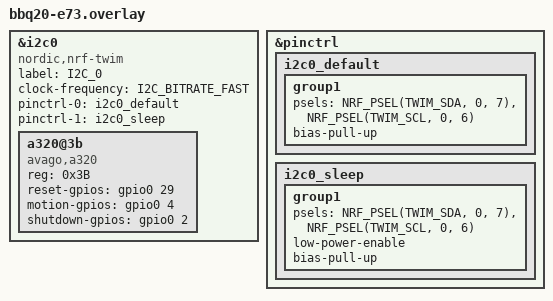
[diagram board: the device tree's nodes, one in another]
&i2c0 {
    a320@3b {
        compatible = "avago,a320";
        status = "okay";
        reg = <0x3B>;
        reset-gpios = <&gpio0 29 GPIO_ACTIVE_HIGH>;  // 复位引脚
        motion-gpios = <&gpio0 4 GPIO_ACTIVE_HIGH>; // 运动中断引脚
        shutdown-gpios= <&gpio0 2 GPIO_ACTIVE_HIGH>; // 休眠引脚
        
    };
    
	label = "I2C_0";
	compatible = "nordic,nrf-twim";
	status = "okay";
	clock-frequency = <I2C_BITRATE_FAST>; 
	pinctrl-0 = <&i2c0_default>;
	pinctrl-1 = <&i2c0_sleep>;
	pinctrl-names = "default", "sleep";
};

&pinctrl {
    i2c0_default: i2c0_default {
		group1 {
			psels = <NRF_PSEL(TWIM_SDA, 0, 7)>,
              <NRF_PSEL(TWIM_SCL, 0, 6)>;
			bias-pull-up;
		};
	};
	i2c0_sleep: i2c0_sleep {
		group1 {
			psels = <NRF_PSEL(TWIM_SDA, 0, 7)>,
              <NRF_PSEL(TWIM_SCL, 0, 6)>;
			low-power-enable;
			bias-pull-up;
		};
	};
};
